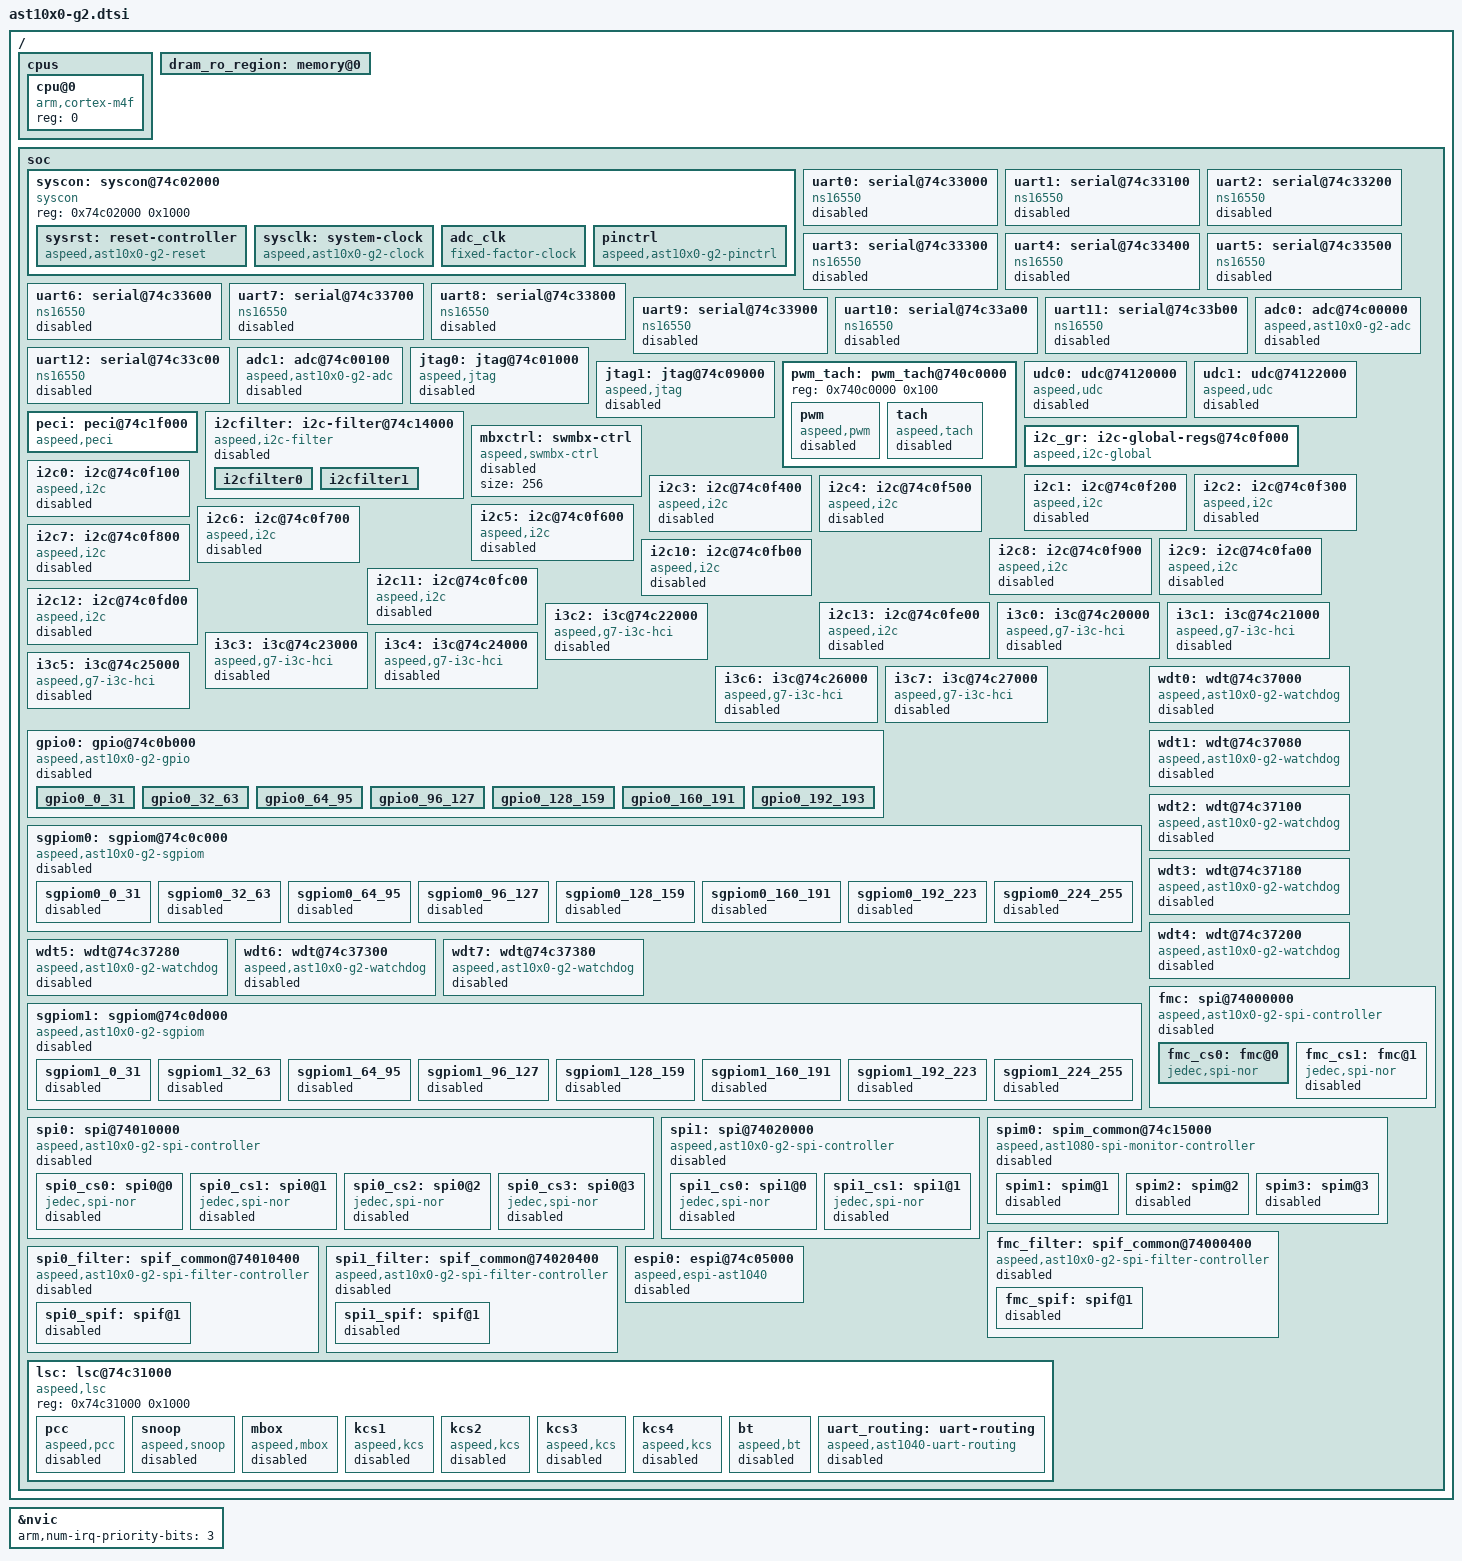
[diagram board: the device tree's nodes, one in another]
/*
 * SPDX-License-Identifier: Apache-2.0
 *
 * Copyright (c) 2023 ASPEED Technology Inc.
 */

#include <arm/armv7-m.dtsi>
#include <mem.h>
#include <aspeed/ast10x0-g2-irq.h>
#include <zephyr/dt-bindings/i2c/i2c.h>
#include <zephyr/dt-bindings/clock/ast10x0_g2_clock.h>
#include <zephyr/dt-bindings/reset/ast10x0-g2_reset.h>
#include <zephyr/dt-bindings/pinctrl/ast10x0-g2-pinctrl-groups.h>

/ {
	cpus {
		#address-cells = <1>;
		#size-cells = <0>;

		cpu@0 {
			device_type = "cpu";
			compatible = "arm,cortex-m4f";
			reg = <0>;
		};
	};

	dram_ro_region: memory@0 {
		device_type = "memory";
	};

	soc {
		syscon: syscon@74c02000 {
			compatible = "syscon";
			reg = <0x74c02000 0x1000>;
			#address-cells = <1>;
			#size-cells = <1>;
			ranges;
			sysrst: reset-controller {
				compatible = "aspeed,ast10x0-g2-reset", "aspeed,ast27xx-reset";
				#reset-cells = <1>;
			};

			sysclk: system-clock {
				compatible = "aspeed,ast10x0-g2-clock";
				#clock-cells = <1>;
			};

			adc_clk: adc_clk {
				#clock-cells = <0>;
				compatible = "fixed-factor-clock";
				clocks = <&sysclk SCU1_CLK_APB>;
				clock-mult = <1>;
				clock-div = <2>;
			};

			pinctrl: pinctrl {
				compatible = "aspeed,ast10x0-g2-pinctrl", "aspeed,g7-soc1-pinctrl";
			};
		};

		uart0: serial@74c33000 {
			compatible = "ns16550";
			reg = <0x74c33000 0x100>;
			interrupts = <INTR_UART0 AST10X0_G2_IRQ_DEFAULT_PRIORITY>;
			clocks = <&sysclk SCU1_CLK_GATE_UART0CLK>;
			status = "disabled";
			reg-shift = <2>;
		};

		uart1: serial@74c33100 {
			compatible = "ns16550";
			reg = <0x74c33100 0x100>;
			interrupts = <INTR_UART1 AST10X0_G2_IRQ_DEFAULT_PRIORITY>;
			clocks = <&sysclk SCU1_CLK_GATE_UART1CLK>;
			status = "disabled";
			reg-shift = <2>;
		};

		uart2: serial@74c33200 {
			compatible = "ns16550";
			reg = <0x74c33200 0x100>;
			interrupts = <INTR_UART2 AST10X0_G2_IRQ_DEFAULT_PRIORITY>;
			clocks = <&sysclk SCU1_CLK_GATE_UART2CLK>;
			pinctrl-0 = <pinctrl_uart2_default>;
			pinctrl-names = "default";
			status = "disabled";
			reg-shift = <2>;
		};

		uart3: serial@74c33300 {
			compatible = "ns16550";
			reg = <0x74c33300 0x100>;
			interrupts = <INTR_UART3 AST10X0_G2_IRQ_DEFAULT_PRIORITY>;
			clocks = <&sysclk SCU1_CLK_GATE_UART3CLK>;
			pinctrl-0 = <pinctrl_uart3_default>;
			pinctrl-names = "default";
			status = "disabled";
			reg-shift = <2>;
		};

		uart4: serial@74c33400 {
			compatible = "ns16550";
			reg = <0x74c33400 0x100>;
			interrupts = <INTR_UART4 AST10X0_G2_IRQ_DEFAULT_PRIORITY>;
			clocks = <&sysclk SCU1_CLK_UART4>;
			pinctrl-0 = <pinctrl_uart4_default>;
			pinctrl-names = "default";
			status = "disabled";
			reg-shift = <2>;
		};

		uart5: serial@74c33500 {
			compatible = "ns16550";
			reg = <0x74c33500 0x100>;
			interrupts = <INTR_UART5 AST10X0_G2_IRQ_DEFAULT_PRIORITY>;
			clocks = <&sysclk SCU1_CLK_GATE_UART5CLK>;
			pinctrl-0 = <pinctrl_uart5_default>;
			pinctrl-names = "default";
			status = "disabled";
			reg-shift = <2>;
		};

		uart6: serial@74c33600 {
			compatible = "ns16550";
			reg = <0x74c33600 0x100>;
			interrupts = <INTR_UART6 AST10X0_G2_IRQ_DEFAULT_PRIORITY>;
			clocks = <&sysclk SCU1_CLK_GATE_UART6CLK>;
			pinctrl-0 = <pinctrl_uart6_default>;
			pinctrl-names = "default";
			status = "disabled";
			reg-shift = <2>;
		};

		uart7: serial@74c33700 {
			compatible = "ns16550";
			reg = <0x74c33700 0x100>;
			interrupts = <INTR_UART7 AST10X0_G2_IRQ_DEFAULT_PRIORITY>;
			clocks = <&sysclk SCU1_CLK_GATE_UART7CLK>;
			pinctrl-0 = <pinctrl_uart7_default>;
			pinctrl-names = "default";
			status = "disabled";
			reg-shift = <2>;
		};

		uart8: serial@74c33800 {
			compatible = "ns16550";
			reg = <0x74c33800 0x100>;
			interrupts = <INTR_UART8 AST10X0_G2_IRQ_DEFAULT_PRIORITY>;
			clocks = <&sysclk SCU1_CLK_GATE_UART8CLK>;
			pinctrl-0 = <pinctrl_uart8_default>;
			pinctrl-names = "default";
			status = "disabled";
			reg-shift = <2>;
		};

		uart9: serial@74c33900 {
			compatible = "ns16550";
			reg = <0x74c33900 0x100>;
			interrupts = <INTR_UART9 AST10X0_G2_IRQ_DEFAULT_PRIORITY>;
			clocks = <&sysclk SCU1_CLK_GATE_UART9CLK>;
			pinctrl-0 = <pinctrl_uart9_default>;
			pinctrl-names = "default";
			status = "disabled";
			reg-shift = <2>;
		};

		uart10: serial@74c33a00 {
			compatible = "ns16550";
			reg = <0x74c33a00 0x100>;
			interrupts = <INTR_UART10 AST10X0_G2_IRQ_DEFAULT_PRIORITY>;
			clocks = <&sysclk SCU1_CLK_GATE_UART10CLK>;
			pinctrl-0 = <pinctrl_uart10_default>;
			pinctrl-names = "default";
			status = "disabled";
			reg-shift = <2>;
		};

		uart11: serial@74c33b00 {
			compatible = "ns16550";
			reg = <0x74c33b00 0x100>;
			interrupts = <INTR_UART11 AST10X0_G2_IRQ_DEFAULT_PRIORITY>;
			clocks = <&sysclk SCU1_CLK_GATE_UART11CLK>;
			pinctrl-0 = <pinctrl_uart11_default>;
			pinctrl-names = "default";
			status = "disabled";
			reg-shift = <2>;
		};

		uart12: serial@74c33c00 {
			compatible = "ns16550";
			reg = <0x74c33c00 0x100>;
			interrupts = <INTR_UART12 AST10X0_G2_IRQ_DEFAULT_PRIORITY>;
			clocks = <&sysclk SCU1_CLK_GATE_UART12CLK>;
			status = "disabled";
			reg-shift = <2>;
		};

		adc0: adc@74c00000 {
			compatible = "aspeed,ast10x0-g2-adc";
			reg = <0x74c00000 0x100>;
			clocks = <&adc_clk>;
			resets = <&sysrst SCU1_RESET_ADC>;
			interrupts = <INTR_ADC AST10X0_G2_IRQ_DEFAULT_PRIORITY>;
			#io-channel-cells = <1>;
			aspeed,scu = <&syscon>;
			aspeed,trim-data-locate = <0x9A0 0xf>;
			status = "disabled";
		};

		adc1: adc@74c00100 {
			compatible = "aspeed,ast10x0-g2-adc";
			reg = <0x74c00100 0x100>;
			clocks = <&adc_clk>;
			resets = <&sysrst SCU1_RESET_ADC>;
			interrupts = <INTR_ADC AST10X0_G2_IRQ_DEFAULT_PRIORITY>;
			#io-channel-cells = <1>;
			aspeed,scu = <&syscon>;
			aspeed,trim-data-locate = <0x9A0 0xf0>;
			status = "disabled";
		};

		jtag0: jtag@74c01000 {
			compatible = "aspeed,jtag";
			reg = <0x74c01000 0x100>;
			clocks = <&sysclk SCU1_CLK_AHB>;
			resets = <&sysrst SCU1_RESET_JTAG0>;
			interrupts = <INTR_JTAGM0 AST10X0_G2_IRQ_DEFAULT_PRIORITY>;
			pinctrl-0 = <pinctrl_jtagm0_default>;
			pinctrl-names = "default";
			status = "disabled";
		};

		jtag1: jtag@74c09000 {
			compatible = "aspeed,jtag";
			reg = <0x74c09000 0x100>;
			clocks = <&sysclk SCU1_CLK_AHB>;
			resets = <&sysrst SCU1_RESET_JTAG1>;
			interrupts = <INTR_JTAGM1 AST10X0_G2_IRQ_DEFAULT_PRIORITY>;
			pinctrl-0 = <pinctrl_jtagm1_default>;
			pinctrl-names = "default";
			status = "disabled";
		};

		pwm_tach: pwm_tach@740c0000 {
			reg = <0x740c0000 0x100>;
			pwm: pwm {
				compatible = "aspeed,pwm";
				#pwm-cells = <3>;
				npwms = <16>;
				clocks = <&sysclk SCU1_CLK_AHB>;
				resets = <&sysrst SCU1_RESET_PWM>;
				status = "disabled";
			};
			tach: tach {
				compatible = "aspeed,tach";
				#address-cells = <1>;
				#size-cells = <0>;
				clocks = <&sysclk SCU1_CLK_AHB>;
				resets = <&sysrst SCU1_RESET_PWM>;
				interrupts = <INTR_TACH AST10X0_G2_IRQ_DEFAULT_PRIORITY>;
				status = "disabled";
			};
		};

		udc0: udc@74120000 {
			compatible = "aspeed,udc";
			reg = <0x74120000 0x1000>;
			interrupts = <INTR_USB2C AST10X0_G2_IRQ_DEFAULT_PRIORITY>;
			num-bidir-endpoints = <22>;
			clocks = <&sysclk SCU1_CLK_GATE_USB2ACLK>;
			resets = <&sysrst SCU1_RESET_PORTC_VHUB_EHCI>;
			pinctrl-0 = <pinctrl_usb2ad_default>;
			pinctrl-names = "default";
			status = "disabled";
		};

		udc1: udc@74122000 {
			compatible = "aspeed,udc";
			reg = <0x74122000 0x1000>;
			interrupts = <INTR_USB2D AST10X0_G2_IRQ_DEFAULT_PRIORITY>;
			num-bidir-endpoints = <22>;
			clocks = <&sysclk SCU1_CLK_GATE_USB2BCLK>;
			resets = <&sysrst SCU1_RESET_PORTD_VHUB_EHCI>;
			pinctrl-0 = <pinctrl_usb2bd_default>;
			pinctrl-names = "default";
			status = "disabled";
		};

		peci: peci@74c1f000 {
			compatible = "aspeed,peci";
			reg = <0x74c1f000 0x100>;
			interrupts = <INTR_PECI AST10X0_G2_IRQ_DEFAULT_PRIORITY>;
			clocks = <&sysclk SCU1_CLK_AHB>;
			resets = <&sysrst SCU1_RESET_PECI>;
			#address-cells = <1>;
			#size-cells = <0>;
		};

		i2cfilter: i2c-filter@74c14000 {
			compatible = "aspeed,i2c-filter";
			reg = <0x74c14000 0x1000>;
			clocks = <&sysclk SCU1_CLK_APB>;
			interrupts = <INTR_I2C_F0 AST10X0_G2_IRQ_DEFAULT_PRIORITY>,
						 <INTR_I2C_F1 AST10X0_G2_IRQ_DEFAULT_PRIORITY>;
			pinctrl-0 = <pinctrl_smbflt1_default pinctrl_smbflt2_default>;
			pinctrl-names = "default";
			status = "disabled";
			i2cfilter0: i2cfilter0 {
				index = <0>;
				clock = <100>;
			};
			i2cfilter1: i2cfilter1 {
				index = <1>;
				clock = <100>;
			};
		};

		mbxctrl: swmbx-ctrl {
			compatible = "aspeed,swmbx-ctrl";
			size = <256>;
			status = "disabled";
		};

		i2c_gr: i2c-global-regs@74c0f000 {
			compatible = "aspeed,i2c-global";
			#address-cells = <1>;
			#size-cells = <0>;
			reg = <0x74c0f000 0x100>;
			clocks = <&sysclk SCU1_CLK_APB>;
			resets = <&sysrst SCU1_RESET_I2C>;
			clk-divider = <0xC6411208>;
		};

		i2c0: i2c@74c0f100 {
			compatible = "aspeed,i2c";
			clock-frequency = <I2C_BITRATE_FAST>;
			#address-cells = <1>;
			#size-cells = <0>;
			reg = <0x74c0f100 0x100>, <0x74c0f1c0 0x40>;
			interrupts = <INTR_I2C0 1>;
			clocks = <&sysclk SCU1_CLK_APB>;
			xfer-mode = "DMA";
			multi-master = <0>;
			smbus-timeout = <1>;
			manual-high-count = <0>;
			manual-low-count = <0>;
			manual-sda-delay = <0>;
			pinctrl-0 = <pinctrl_i2c0_default>;
			pinctrl-names = "default";
			status = "disabled";
		};

		i2c1: i2c@74c0f200 {
			compatible = "aspeed,i2c";
			clock-frequency = <I2C_BITRATE_FAST>;
			#address-cells = <1>;
			#size-cells = <0>;
			reg = <0x74c0f200 0x100>, <0x74c0f2c0 0x40>;
			interrupts = <INTR_I2C1 1>;
			clocks = <&sysclk SCU1_CLK_APB>;
			xfer-mode = "DMA";
			multi-master = <0>;
			smbus-timeout = <1>;
			manual-high-count = <0>;
			manual-low-count = <0>;
			manual-sda-delay = <0>;
			pinctrl-0 = <pinctrl_i2c1_default>;
			pinctrl-names = "default";
			status = "disabled";
		};

		i2c2: i2c@74c0f300 {
			compatible = "aspeed,i2c";
			clock-frequency = <I2C_BITRATE_FAST>;
			#address-cells = <1>;
			#size-cells = <0>;
			reg = <0x74c0f300 0x100>, <0x74c0f3c0 0x40>;
			interrupts = <INTR_I2C2 1>;
			clocks = <&sysclk SCU1_CLK_APB>;
			xfer-mode = "DMA";
			multi-master = <0>;
			smbus-timeout = <1>;
			manual-high-count = <0>;
			manual-low-count = <0>;
			manual-sda-delay = <0>;
			pinctrl-0 = <pinctrl_i2c2_default>;
			pinctrl-names = "default";
			status = "disabled";
		};

		i2c3: i2c@74c0f400 {
			compatible = "aspeed,i2c";
			clock-frequency = <I2C_BITRATE_FAST>;
			#address-cells = <1>;
			#size-cells = <0>;
			reg = <0x74c0f400 0x100>, <0x74c0f4c0 0x40>;
			interrupts = <INTR_I2C3 1>;
			clocks = <&sysclk SCU1_CLK_APB>;
			xfer-mode = "DMA";
			multi-master = <0>;
			smbus-timeout = <1>;
			manual-high-count = <0>;
			manual-low-count = <0>;
			manual-sda-delay = <0>;
			pinctrl-0 = <pinctrl_i2c3_default>;
			pinctrl-names = "default";
			status = "disabled";
		};

		i2c4: i2c@74c0f500 {
			compatible = "aspeed,i2c";
			clock-frequency = <I2C_BITRATE_FAST>;
			#address-cells = <1>;
			#size-cells = <0>;
			reg = <0x74c0f500 0x100>, <0x74c0f5c0 0x40>;
			interrupts = <INTR_I2C4 1>;
			clocks = <&sysclk SCU1_CLK_APB>;
			xfer-mode = "DMA";
			multi-master = <0>;
			smbus-timeout = <1>;
			manual-high-count = <0>;
			manual-low-count = <0>;
			manual-sda-delay = <0>;
			pinctrl-0 = <pinctrl_i2c4_default>;
			pinctrl-names = "default";
			status = "disabled";
		};

		i2c5: i2c@74c0f600 {
			compatible = "aspeed,i2c";
			clock-frequency = <I2C_BITRATE_FAST>;
			#address-cells = <1>;
			#size-cells = <0>;
			reg = <0x74c0f600 0x100>, <0x74c0f6c0 0x40>;
			interrupts = <INTR_I2C5 1>;
			clocks = <&sysclk SCU1_CLK_APB>;
			xfer-mode = "DMA";
			multi-master = <0>;
			smbus-timeout = <1>;
			manual-high-count = <0>;
			manual-low-count = <0>;
			manual-sda-delay = <0>;
			pinctrl-0 = <pinctrl_i2c5_default>;
			pinctrl-names = "default";
			status = "disabled";
		};

		i2c6: i2c@74c0f700 {
			compatible = "aspeed,i2c";
			clock-frequency = <I2C_BITRATE_FAST>;
			#address-cells = <1>;
			#size-cells = <0>;
			reg = <0x74c0f700 0x100>, <0x74c0f7c0 0x40>;
			interrupts = <INTR_I2C6 1>;
			clocks = <&sysclk SCU1_CLK_APB>;
			xfer-mode = "DMA";
			multi-master = <0>;
			smbus-timeout = <1>;
			manual-high-count = <0>;
			manual-low-count = <0>;
			manual-sda-delay = <0>;
			pinctrl-0 = <pinctrl_i2c6_default>;
			pinctrl-names = "default";
			status = "disabled";
		};

		i2c7: i2c@74c0f800 {
			compatible = "aspeed,i2c";
			clock-frequency = <I2C_BITRATE_FAST>;
			#address-cells = <1>;
			#size-cells = <0>;
			reg = <0x74c0f800 0x100>, <0x74c0f8c0 0x40>;
			interrupts = <INTR_I2C7 1>;
			clocks = <&sysclk SCU1_CLK_APB>;
			xfer-mode = "DMA";
			multi-master = <0>;
			smbus-timeout = <1>;
			manual-high-count = <0>;
			manual-low-count = <0>;
			manual-sda-delay = <0>;
			pinctrl-0 = <pinctrl_i2c7_default>;
			pinctrl-names = "default";
			status = "disabled";
		};

		i2c8: i2c@74c0f900 {
			compatible = "aspeed,i2c";
			clock-frequency = <I2C_BITRATE_FAST>;
			#address-cells = <1>;
			#size-cells = <0>;
			reg = <0x74c0f900 0x100>, <0x74c0f9c0 0x40>;
			interrupts = <INTR_I2C8 1>;
			clocks = <&sysclk SCU1_CLK_APB>;
			xfer-mode = "DMA";
			multi-master = <0>;
			smbus-timeout = <1>;
			manual-high-count = <0>;
			manual-low-count = <0>;
			manual-sda-delay = <0>;
			pinctrl-0 = <pinctrl_i2c8_default>;
			pinctrl-names = "default";
			status = "disabled";
		};

		i2c9: i2c@74c0fa00 {
			compatible = "aspeed,i2c";
			clock-frequency = <I2C_BITRATE_FAST>;
			#address-cells = <1>;
			#size-cells = <0>;
			reg = <0x74c0fa00 0x100>, <0x74c0fac0 0x40>;
			interrupts = <INTR_I2C9 1>;
			clocks = <&sysclk SCU1_CLK_APB>;
			xfer-mode = "DMA";
			multi-master = <0>;
			smbus-timeout = <1>;
			manual-high-count = <0>;
			manual-low-count = <0>;
			manual-sda-delay = <0>;
			pinctrl-0 = <pinctrl_i2c9_default>;
			pinctrl-names = "default";
			status = "disabled";
		};

		i2c10: i2c@74c0fb00 {
			compatible = "aspeed,i2c";
			clock-frequency = <I2C_BITRATE_FAST>;
			#address-cells = <1>;
			#size-cells = <0>;
			reg = <0x74c0fb00 0x100>, <0x74c0fbc0 0x40>;
			interrupts = <INTR_I2C10 1>;
			clocks = <&sysclk SCU1_CLK_APB>;
			xfer-mode = "DMA";
			multi-master = <0>;
			smbus-timeout = <1>;
			manual-high-count = <0>;
			manual-low-count = <0>;
			manual-sda-delay = <0>;
			pinctrl-0 = <pinctrl_i2c10_default>;
			pinctrl-names = "default";
			status = "disabled";
		};

		i2c11: i2c@74c0fc00 {
			compatible = "aspeed,i2c";
			clock-frequency = <I2C_BITRATE_FAST>;
			#address-cells = <1>;
			#size-cells = <0>;
			reg = <0x74c0fc00 0x100>, <0x74c0fcc0 0x40>;
			interrupts = <INTR_I2C11 1>;
			clocks = <&sysclk SCU1_CLK_APB>;
			xfer-mode = "DMA";
			multi-master = <0>;
			smbus-timeout = <1>;
			manual-high-count = <0>;
			manual-low-count = <0>;
			manual-sda-delay = <0>;
			pinctrl-0 = <pinctrl_i2c11_default>;
			pinctrl-names = "default";
			status = "disabled";
		};

		i2c12: i2c@74c0fd00 {
			compatible = "aspeed,i2c";
			clock-frequency = <I2C_BITRATE_FAST>;
			#address-cells = <1>;
			#size-cells = <0>;
			reg = <0x74c0fd00 0x100>, <0x74c0fdc0 0x40>;
			interrupts = <INTR_I2C12 1>;
			clocks = <&sysclk SCU1_CLK_APB>;
			xfer-mode = "DMA";
			multi-master = <0>;
			smbus-timeout = <1>;
			manual-high-count = <0>;
			manual-low-count = <0>;
			manual-sda-delay = <0>;
			pinctrl-0 = <pinctrl_i2c12_default>;
			pinctrl-names = "default";
			status = "disabled";
		};

		i2c13: i2c@74c0fe00 {
			compatible = "aspeed,i2c";
			clock-frequency = <I2C_BITRATE_FAST>;
			#address-cells = <1>;
			#size-cells = <0>;
			reg = <0x74c0fe00 0x100>, <0x74c0fec0 0x40>;
			interrupts = <INTR_I2C13 1>;
			clocks = <&sysclk SCU1_CLK_APB>;
			xfer-mode = "DMA";
			multi-master = <0>;
			smbus-timeout = <1>;
			manual-high-count = <0>;
			manual-low-count = <0>;
			manual-sda-delay = <0>;
			pinctrl-0 = <pinctrl_i2c13_default>;
			pinctrl-names = "default";
			status = "disabled";
		};

		i3c0: i3c@74c20000 {
			compatible = "aspeed,g7-i3c-hci";
			reg = <0x74c20000 0x1000>;
			interrupts = <INTR_I3C0 AST10X0_G2_IRQ_DEFAULT_PRIORITY>;
			clocks = <&sysclk SCU1_CLK_GATE_I3C0CLK>;
			resets = <&sysrst SCU1_RESET_I3C0>, <&sysrst SCU1_RESET_I3CDMA>;
			reset-names = "core", "dma";
			i2c-scl-hz = <1000000>;
			i3c-scl-hz = <12500000>;
			io-mode = "pio";
			pinctrl-0 = <pinctrl_i3c0_default>;
			pinctrl-names = "default";
			status = "disabled";
			#address-cells = <3>;
			#size-cells = <0>;
		};

		i3c1: i3c@74c21000 {
			compatible = "aspeed,g7-i3c-hci";
			reg = <0x74c21000 0x1000>;
			interrupts = <INTR_I3C1 AST10X0_G2_IRQ_DEFAULT_PRIORITY>;
			clocks = <&sysclk SCU1_CLK_GATE_I3C1CLK>;
			resets = <&sysrst SCU1_RESET_I3C1>, <&sysrst SCU1_RESET_I3CDMA>;
			reset-names = "core", "dma";
			i2c-scl-hz = <1000000>;
			i3c-scl-hz = <12500000>;
			io-mode = "pio";
			pinctrl-0 = <pinctrl_i3c1_default>;
			pinctrl-names = "default";
			status = "disabled";
			#address-cells = <3>;
			#size-cells = <0>;
		};

		i3c2: i3c@74c22000 {
			compatible = "aspeed,g7-i3c-hci";
			reg = <0x74c22000 0x1000>;
			interrupts = <INTR_I3C2 AST10X0_G2_IRQ_DEFAULT_PRIORITY>;
			clocks = <&sysclk SCU1_CLK_GATE_I3C2CLK>;
			resets = <&sysrst SCU1_RESET_I3C2>, <&sysrst SCU1_RESET_I3CDMA>;
			reset-names = "core", "dma";
			i2c-scl-hz = <1000000>;
			i3c-scl-hz = <12500000>;
			io-mode = "pio";
			pinctrl-0 = <pinctrl_i3c2_default>;
			pinctrl-names = "default";
			status = "disabled";
			#address-cells = <3>;
			#size-cells = <0>;
		};

		i3c3: i3c@74c23000 {
			compatible = "aspeed,g7-i3c-hci";
			reg = <0x74c23000 0x1000>;
			interrupts = <INTR_I3C3 AST10X0_G2_IRQ_DEFAULT_PRIORITY>;
			clocks = <&sysclk SCU1_CLK_GATE_I3C3CLK>;
			resets = <&sysrst SCU1_RESET_I3C3>, <&sysrst SCU1_RESET_I3CDMA>;
			reset-names = "core", "dma";
			i2c-scl-hz = <1000000>;
			i3c-scl-hz = <12500000>;
			io-mode = "pio";
			pinctrl-0 = <pinctrl_i3c3_default>;
			pinctrl-names = "default";
			status = "disabled";
			#address-cells = <3>;
			#size-cells = <0>;
		};

		i3c4: i3c@74c24000 {
			compatible = "aspeed,g7-i3c-hci";
			reg = <0x74c24000 0x1000>;
			interrupts = <INTR_I3C4 AST10X0_G2_IRQ_DEFAULT_PRIORITY>;
			clocks = <&sysclk SCU1_CLK_GATE_I3C4CLK>;
			resets = <&sysrst SCU1_RESET_I3C4>, <&sysrst SCU1_RESET_I3CDMA>;
			reset-names = "core", "dma";
			i2c-scl-hz = <1000000>;
			i3c-scl-hz = <12500000>;
			io-mode = "pio";
			pinctrl-0 = <pinctrl_i3c4_default>;
			pinctrl-names = "default";
			status = "disabled";
			#address-cells = <3>;
			#size-cells = <0>;
		};

		i3c5: i3c@74c25000 {
			compatible = "aspeed,g7-i3c-hci";
			reg = <0x74c25000 0x1000>;
			interrupts = <INTR_I3C5 AST10X0_G2_IRQ_DEFAULT_PRIORITY>;
			clocks = <&sysclk SCU1_CLK_GATE_I3C5CLK>;
			resets = <&sysrst SCU1_RESET_I3C5>, <&sysrst SCU1_RESET_I3CDMA>;
			reset-names = "core", "dma";
			i2c-scl-hz = <1000000>;
			i3c-scl-hz = <12500000>;
			io-mode = "pio";
			pinctrl-0 = <pinctrl_i3c5_default>;
			pinctrl-names = "default";
			status = "disabled";
			#address-cells = <3>;
			#size-cells = <0>;
		};

		i3c6: i3c@74c26000 {
			compatible = "aspeed,g7-i3c-hci";
			reg = <0x74c26000 0x1000>;
			interrupts = <INTR_I3C6 AST10X0_G2_IRQ_DEFAULT_PRIORITY>;
			clocks = <&sysclk SCU1_CLK_GATE_I3C6CLK>;
			resets = <&sysrst SCU1_RESET_I3C6>, <&sysrst SCU1_RESET_I3CDMA>;
			reset-names = "core", "dma";
			i2c-scl-hz = <1000000>;
			i3c-scl-hz = <12500000>;
			io-mode = "pio";
			pinctrl-0 = <pinctrl_i3c6_default>;
			pinctrl-names = "default";
			status = "disabled";
			#address-cells = <3>;
			#size-cells = <0>;
		};

		i3c7: i3c@74c27000 {
			compatible = "aspeed,g7-i3c-hci";
			reg = <0x74c27000 0x1000>;
			interrupts = <INTR_I3C7 AST10X0_G2_IRQ_DEFAULT_PRIORITY>;
			clocks = <&sysclk SCU1_CLK_GATE_I3C7CLK>;
			resets = <&sysrst SCU1_RESET_I3C7>, <&sysrst SCU1_RESET_I3CDMA>;
			reset-names = "core", "dma";
			i2c-scl-hz = <1000000>;
			i3c-scl-hz = <12500000>;
			io-mode = "pio";
			pinctrl-0 = <pinctrl_i3c7_default>;
			pinctrl-names = "default";
			status = "disabled";
			#address-cells = <3>;
			#size-cells = <0>;
		};

		gpio0: gpio@74c0b000 {
			compatible = "aspeed,ast10x0-g2-gpio", "aspeed,g7-gpio";
			reg = <0x74c0b000 0x1000>;
			interrupts = <INTR_GPIO AST10X0_G2_IRQ_DEFAULT_PRIORITY>;
			clocks = <&sysclk SCU1_CLK_AHB>;
			ngpios = <194>;
			status = "disabled";

			gpio0_0_31: gpio0_0_31 {
				#gpio-cells = <2>;
				gpio-controller;
				pin-offset = <0>;
			};
			gpio0_32_63: gpio0_32_63 {
				#gpio-cells = <2>;
				gpio-controller;
				pin-offset = <32>;
				gpio-reserved = <0xf0000000>;
			};
			gpio0_64_95: gpio0_64_95 {
				#gpio-cells = <2>;
				gpio-controller;
				pin-offset = <64>;
			};
			gpio0_96_127: gpio0_96_127 {
				#gpio-cells = <2>;
				gpio-controller;
				pin-offset = <96>;
			};
			gpio0_128_159: gpio0_128_159 {
				#gpio-cells = <2>;
				gpio-controller;
				pin-offset = <128>;
			};
			gpio0_160_191: gpio0_160_191 {
				#gpio-cells = <2>;
				gpio-controller;
				pin-offset = <160>;
			};
			gpio0_192_193: gpio0_192_193 {
				#gpio-cells = <2>;
				gpio-controller;
				ngpios = <2>;
				pin-offset = <192>;
			};
		};

		sgpiom0: sgpiom@74c0c000 {
			compatible = "aspeed,ast10x0-g2-sgpiom", "aspeed,g7-sgpiom";
			reg = <0x74c0c000 0x100>;
			interrupts = <INTR_SGPIO0 AST10X0_G2_IRQ_DEFAULT_PRIORITY>;
			clocks = <&sysclk SCU1_CLK_APB>;
			pinctrl-0 = <pinctrl_sgpm0_default>;
			pinctrl-names = "default";
			aspeed,bus-freq = <12000000>;
			ngpios = <256>;
			status = "disabled";

			sgpiom0_0_31: sgpiom0_0_31 {
				#gpio-cells = <2>;
				gpio-controller;
				pin-offset = <0>;
				status = "disabled";
			};
			sgpiom0_32_63: sgpiom0_32_63 {
				#gpio-cells = <2>;
				gpio-controller;
				pin-offset = <32>;
				status = "disabled";
			};
			sgpiom0_64_95: sgpiom0_64_95 {
				#gpio-cells = <2>;
				gpio-controller;
				pin-offset = <64>;
				status = "disabled";
			};
			sgpiom0_96_127: sgpiom0_96_127 {
				#gpio-cells = <2>;
				gpio-controller;
				pin-offset = <96>;
				status = "disabled";
			};
			sgpiom0_128_159: sgpiom0_128_159 {
				#gpio-cells = <2>;
				gpio-controller;
				pin-offset = <128>;
				status = "disabled";
			};
			sgpiom0_160_191: sgpiom0_160_191 {
				#gpio-cells = <2>;
				gpio-controller;
				pin-offset = <160>;
				status = "disabled";
			};
			sgpiom0_192_223: sgpiom0_192_223 {
				#gpio-cells = <2>;
				gpio-controller;
				pin-offset = <192>;
				status = "disabled";
			};
			sgpiom0_224_255: sgpiom0_224_255 {
				#gpio-cells = <2>;
				gpio-controller;
				pin-offset = <224>;
				status = "disabled";
			};
		};

		wdt0: wdt@74c37000 {
			compatible = "aspeed,ast10x0-g2-watchdog";
			reg = <0x74c37000 0x80>;
			aspeed,scu = <&syscon>;
			interrupts = <INTR_WDT0 AST10X0_G2_IRQ_DEFAULT_PRIORITY>;
			reset-mask = <0x000019ec 0x2010e803 0x003e0000>;
			status = "disabled";
		};

		wdt1: wdt@74c37080 {
			compatible = "aspeed,ast10x0-g2-watchdog";
			reg = <0x74c37080 0x80>;
			aspeed,scu = <&syscon>;
			interrupts = <INTR_WDT1 AST10X0_G2_IRQ_DEFAULT_PRIORITY>;
			reset-mask = <0x000019ec 0x2010e803 0x003e0000>;
			status = "disabled";
		};

		wdt2: wdt@74c37100 {
			compatible = "aspeed,ast10x0-g2-watchdog";
			reg = <0x74c37100 0x80>;
			aspeed,scu = <&syscon>;
			interrupts = <INTR_WDT2 AST10X0_G2_IRQ_DEFAULT_PRIORITY>;
			reset-mask = <0x000019ec 0x2010e803 0x003e0000>;
			status = "disabled";
		};

		wdt3: wdt@74c37180 {
			compatible = "aspeed,ast10x0-g2-watchdog";
			reg = <0x74c37180 0x80>;
			aspeed,scu = <&syscon>;
			interrupts = <INTR_WDT3 AST10X0_G2_IRQ_DEFAULT_PRIORITY>;
			reset-mask = <0x000019ec 0x2010e803 0x003e0000>;
			status = "disabled";
		};

		wdt4: wdt@74c37200 {
			compatible = "aspeed,ast10x0-g2-watchdog";
			reg = <0x74c37200 0x80>;
			aspeed,scu = <&syscon>;
			interrupts = <INTR_WDT4 AST10X0_G2_IRQ_DEFAULT_PRIORITY>;
			reset-mask = <0x000019ec 0x2010e803 0x003e0000>;
			status = "disabled";
		};

		wdt5: wdt@74c37280 {
			compatible = "aspeed,ast10x0-g2-watchdog";
			reg = <0x74c37280 0x80>;
			aspeed,scu = <&syscon>;
			interrupts = <INTR_WDT5 AST10X0_G2_IRQ_DEFAULT_PRIORITY>;
			reset-mask = <0x000019ec 0x2010e803 0x003e0000>;
			status = "disabled";
		};

		wdt6: wdt@74c37300 {
			compatible = "aspeed,ast10x0-g2-watchdog";
			reg = <0x74c37300 0x80>;
			aspeed,scu = <&syscon>;
			interrupts = <INTR_WDT6 AST10X0_G2_IRQ_DEFAULT_PRIORITY>;
			reset-mask = <0x000019ec 0x2010e803 0x003e0000>;
			status = "disabled";
		};

		wdt7: wdt@74c37380 {
			compatible = "aspeed,ast10x0-g2-watchdog";
			reg = <0x74c37380 0x80>;
			aspeed,scu = <&syscon>;
			interrupts = <INTR_WDT7 AST10X0_G2_IRQ_DEFAULT_PRIORITY>;
			reset-mask = <0x000019ec 0x2010e803 0x003e0000>;
			status = "disabled";
		};

		sgpiom1: sgpiom@74c0d000 {
			compatible = "aspeed,ast10x0-g2-sgpiom", "aspeed,g7-sgpiom";
			reg = <0x74c0d000 0x100>;
			interrupts = <INTR_SGPIO1 AST10X0_G2_IRQ_DEFAULT_PRIORITY>;
			clocks = <&sysclk SCU1_CLK_APB>;
			pinctrl-0 = <pinctrl_sgpm1_default>;
			pinctrl-names = "default";
			aspeed,bus-freq = <12000000>;
			ngpios = <256>;
			status = "disabled";

			sgpiom1_0_31: sgpiom1_0_31 {
				#gpio-cells = <2>;
				gpio-controller;
				pin-offset = <0>;
				status = "disabled";
			};
			sgpiom1_32_63: sgpiom1_32_63 {
				#gpio-cells = <2>;
				gpio-controller;
				pin-offset = <32>;
				status = "disabled";
			};
			sgpiom1_64_95: sgpiom1_64_95 {
				#gpio-cells = <2>;
				gpio-controller;
				pin-offset = <64>;
				status = "disabled";
			};
			sgpiom1_96_127: sgpiom1_96_127 {
				#gpio-cells = <2>;
				gpio-controller;
				pin-offset = <96>;
				status = "disabled";
			};
			sgpiom1_128_159: sgpiom1_128_159 {
				#gpio-cells = <2>;
				gpio-controller;
				pin-offset = <128>;
				status = "disabled";
			};
			sgpiom1_160_191: sgpiom1_160_191 {
				#gpio-cells = <2>;
				gpio-controller;
				pin-offset = <160>;
				status = "disabled";
			};
			sgpiom1_192_223: sgpiom1_192_223 {
				#gpio-cells = <2>;
				gpio-controller;
				pin-offset = <192>;
				status = "disabled";
			};
			sgpiom1_224_255: sgpiom1_224_255 {
				#gpio-cells = <2>;
				gpio-controller;
				pin-offset = <224>;
				status = "disabled";
			};
		};

		fmc: spi@74000000 {
			compatible = "aspeed,ast10x0-g2-spi-controller";
			reg = <0x74000000 0x300>, <0x80000000 0x10000000>;
			reg-names = "ctrl_reg", "spi_mmap";
			interrupts = <INTR_FMC AST10X0_G2_IRQ_DEFAULT_PRIORITY>;
			clocks = <&sysclk SCU1_CLK_AHB>;
			pinctrl-0 = <pinctrl_fwspi_quad_default>;
			pinctrl-names = "default";
			num-cs = <2>;
			ctrl-type = "bspi";
			#address-cells = <1>;
			#size-cells = <0>;
			spi-ctrl-caps-mask = <0x000e0e0c>;
			status = "disabled";

			fmc_cs0: fmc@0 {
				compatible = "jedec,spi-nor";
				reg = <0>;
				spi-max-buswidth = <4>;
				spi-max-frequency = <25000000>;
				jedec-id = [];
				status = "okay";
			};

			fmc_cs1: fmc@1 {
				compatible = "jedec,spi-nor";
				reg = <1>;
				spi-max-buswidth = <4>;
				spi-max-frequency = <25000000>;
				jedec-id = [];
				status = "disabled";
			};
		};

		spi0: spi@74010000 {
			compatible = "aspeed,ast10x0-g2-spi-controller";
			reg = <0x74010000 0x300>, <0xA0000000 0x10000000>;
			reg-names = "ctrl_reg", "spi_mmap";
			interrupts = <INTR_SPI0 AST10X0_G2_IRQ_DEFAULT_PRIORITY>;
			clocks = <&sysclk SCU1_CLK_AHB>;
			pinctrl-0 = <pinctrl_spim0_default pinctrl_spim0_quad_default
				     pinctrl_spim0_cs1_default>;
			pinctrl-names = "default";
			num-cs = <4>;
			ctrl-type = "nspi";
			#address-cells = <1>;
			#size-cells = <0>;
			spi-ctrl-caps-mask = <0x000e0e0c>;
			status = "disabled";

			spi0_cs0: spi0@0 {
				compatible = "jedec,spi-nor";
				reg = <0>;
				spi-max-buswidth = <4>;
				spi-max-frequency = <25000000>;
				jedec-id = [];
				status = "disabled";
			};

			spi0_cs1: spi0@1 {
				compatible = "jedec,spi-nor";
				reg = <1>;
				spi-max-buswidth = <4>;
				spi-max-frequency = <25000000>;
				jedec-id = [];
				status = "disabled";
			};

			spi0_cs2: spi0@2 {
				compatible = "jedec,spi-nor";
				reg = <2>;
				spi-max-buswidth = <4>;
				spi-max-frequency = <25000000>;
				jedec-id = [];
				status = "disabled";
			};

			spi0_cs3: spi0@3 {
				compatible = "jedec,spi-nor";
				reg = <3>;
				spi-max-buswidth = <4>;
				spi-max-frequency = <25000000>;
				jedec-id = [];
				status = "disabled";
			};
		};

		spi1: spi@74020000 {
			compatible = "aspeed,ast10x0-g2-spi-controller";
			reg = <0x74020000 0x300>, <0xC0000000 0x10000000>;
			reg-names = "ctrl_reg", "spi_mmap";
			interrupts = <INTR_SPI1 AST10X0_G2_IRQ_DEFAULT_PRIORITY>;
			clocks = <&sysclk SCU1_CLK_AHB>;
			pinctrl-0 = <pinctrl_spim1_default pinctrl_spim1_quad_default
				     pinctrl_spim1_cs1_default>;
			pinctrl-names = "default";
			num-cs = <2>;
			ctrl-type = "nspi";
			#address-cells = <1>;
			#size-cells = <0>;
			spi-ctrl-caps-mask = <0x000e0e0c>;
			status = "disabled";

			spi1_cs0: spi1@0 {
				compatible = "jedec,spi-nor";
				reg = <0>;
				spi-max-buswidth = <4>;
				spi-max-frequency = <25000000>;
				jedec-id = [];
				status = "disabled";
			};

			spi1_cs1: spi1@1 {
				compatible = "jedec,spi-nor";
				reg = <1>;
				spi-max-buswidth = <4>;
				spi-max-frequency = <25000000>;
				jedec-id = [];
				status = "disabled";
			};
		};

		spim0: spim_common@74c15000 {
			compatible = "aspeed,ast1080-spi-monitor-controller";
			reg = <0x74c15000 0x3000>;
			aspeed,scu = <&syscon>;
			#address-cells = <1>;
			#size-cells = <0>;
			status = "disabled";

			spim1: spim@1 {
				interrupts = <INTR_SPI_F0 AST10X0_G2_IRQ_DEFAULT_PRIORITY>;
				reg = <1>;
				allow-cmds = [];
				status = "disabled";
			};

			spim2: spim@2 {
				interrupts = <INTR_SPI_F1 AST10X0_G2_IRQ_DEFAULT_PRIORITY>;
				reg = <2>;
				allow-cmds = [];
				status = "disabled";
			};

			spim3: spim@3 {
				interrupts = <INTR_SPI_F2 AST10X0_G2_IRQ_DEFAULT_PRIORITY>;
				reg = <3>;
				allow-cmds = [];
				status = "disabled";
			};
		};

		fmc_filter: spif_common@74000400 {
			compatible = "aspeed,ast10x0-g2-spi-filter-controller";
			reg = <0x74000400 0x1000>;
			aspeed,scu = <&syscon>;
			#address-cells = <1>;
			#size-cells = <0>;
			status = "disabled";

			fmc_spif: spif@1 {
				label = "fmc_spif";
				interrupts = <INTR_FMC_FILTER AST10X0_G2_IRQ_DEFAULT_PRIORITY>;
				reg = <1>;
				allow-cmds = [];
				status = "disabled";
			};
		};

		spi0_filter: spif_common@74010400 {
			compatible = "aspeed,ast10x0-g2-spi-filter-controller";
			reg = <0x74010400 0x1000>;
			aspeed,scu = <&syscon>;
			#address-cells = <1>;
			#size-cells = <0>;
			status = "disabled";

			spi0_spif: spif@1 {
				label = "spi0_spif";
				interrupts = <INTR_SPI0_FILTER AST10X0_G2_IRQ_DEFAULT_PRIORITY>;
				reg = <1>;
				allow-cmds = [];
				status = "disabled";
			};
		};

		spi1_filter: spif_common@74020400 {
			compatible = "aspeed,ast10x0-g2-spi-filter-controller";
			reg = <0x74020400 0x1000>;
			aspeed,scu = <&syscon>;
			#address-cells = <1>;
			#size-cells = <0>;
			status = "disabled";

			spi1_spif: spif@1 {
				label = "spi1_spif";
				interrupts = <INTR_SPI1_FILTER AST10X0_G2_IRQ_DEFAULT_PRIORITY>;
				reg = <1>;
				allow-cmds = [];
				status = "disabled";
			};
		};

		espi0: espi@74c05000 {
			compatible = "aspeed,espi-ast1040", "aspeed,espi-v2";
			reg = <0x74c05000 0x1000>;
			interrupts = <INTR_ESPI_GLOBAL AST10X0_G2_IRQ_DEFAULT_PRIORITY>;
			clocks = <&sysclk SCU1_CLK_AHB>;
			aspeed,scu = <&syscon>;
			status = "disabled";
		};

		lsc: lsc@74c31000 {
			compatible = "aspeed,lsc";
			reg = <0x74c31000 0x1000>;

			pcc: pcc {
				compatible = "aspeed,pcc";
				interrupts = <INTR_POSTCODE AST10X0_G2_IRQ_DEFAULT_PRIORITY>;
				status = "disabled";
			};

			snoop: snoop {
				compatible = "aspeed,snoop";
				interrupts = <INTR_SNOOP AST10X0_G2_IRQ_DEFAULT_PRIORITY>;
				status = "disabled";
			};

			mbox: mbox {
				compatible = "aspeed,mbox";
				interrupts = <INTR_LPC_MAILBOX AST10X0_G2_IRQ_DEFAULT_PRIORITY>;
				status = "disabled";
			};

			kcs1: kcs1 {
				compatible = "aspeed,kcs";
				interrupts = <INTR_KCS_1 AST10X0_G2_IRQ_DEFAULT_PRIORITY>;
				chan = <1>;
				status = "disabled";
			};

			kcs2: kcs2 {
				compatible = "aspeed,kcs";
				interrupts = <INTR_KCS_2 AST10X0_G2_IRQ_DEFAULT_PRIORITY>;
				chan = <2>;
				status = "disabled";
			};

			kcs3: kcs3 {
				compatible = "aspeed,kcs";
				interrupts = <INTR_KCS_3 AST10X0_G2_IRQ_DEFAULT_PRIORITY>;
				chan = <3>;
				status = "disabled";
			};

			kcs4: kcs4 {
				compatible = "aspeed,kcs";
				interrupts = <INTR_KCS_4 AST10X0_G2_IRQ_DEFAULT_PRIORITY>;
				chan = <4>;
				status = "disabled";
			};

			bt: bt {
				compatible = "aspeed,bt";
				interrupts = <INTR_BT AST10X0_G2_IRQ_DEFAULT_PRIORITY>;
				status = "disabled";
			};

			uart_routing: uart-routing {
				compatible = "aspeed,ast1040-uart-routing", "aspeed,uart-routing";
				status = "disabled";
				ch-name = "uart0", "uart1", "uart2", "uart3", "UART9";
				sel-io = "io0", "io1", "io2", "io3", "io9";
				io-name = "io0", "io1", "io2", "io3", "io9";
				sel-ch = "uart0", "uart1", "uart2", "uart3", "UART9";
			};
		};
	};
};

&nvic {
	arm,num-irq-priority-bits = <3>;
};

#include "ast10x0-g2-pinctrl.dtsi"
